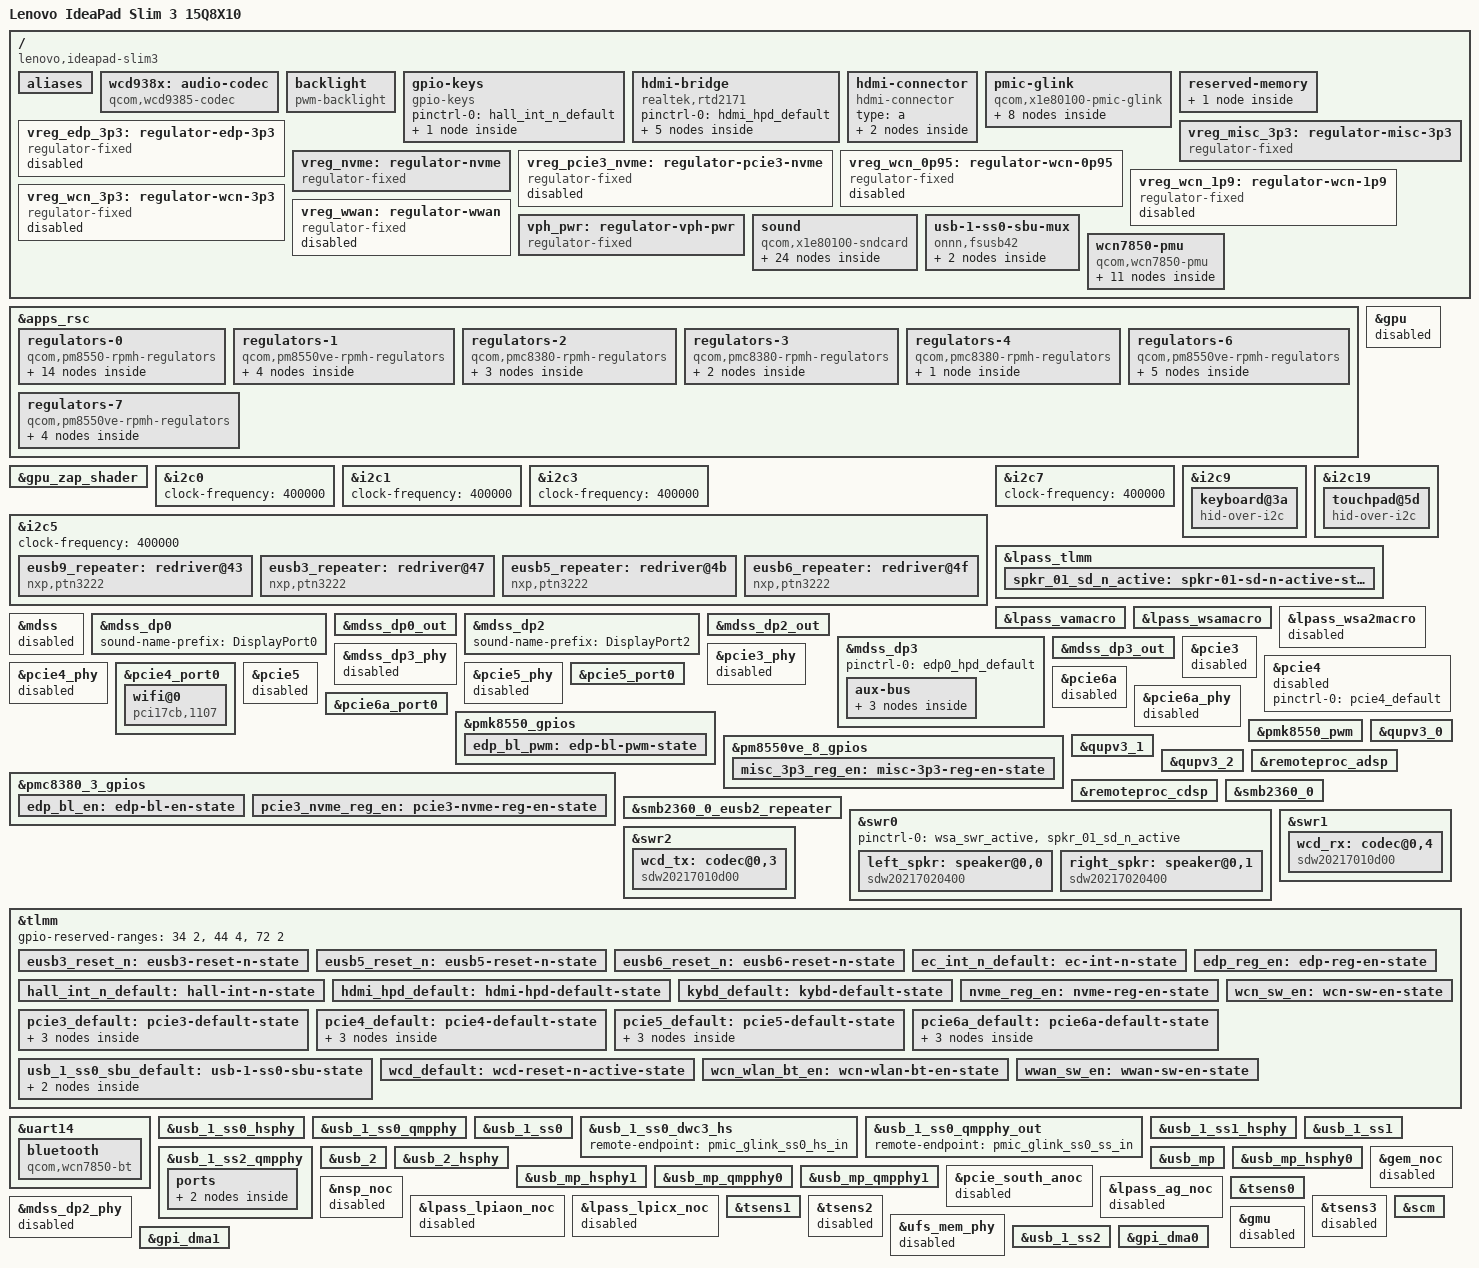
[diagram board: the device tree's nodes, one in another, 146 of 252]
// SPDX-License-Identifier: BSD-3-Clause
/*
 * Copyright (c) 2023 Qualcomm Innovation Center, Inc. All rights reserved.
 * Copyright (c) 2024, Linaro Limited
 * Copyright (c) 2025, Jens Glathe
 */

/dts-v1/;

#include <dt-bindings/gpio/gpio.h>
#include <dt-bindings/input/gpio-keys.h>
#include <dt-bindings/input/input.h>
#include <dt-bindings/pinctrl/qcom,pmic-gpio.h>
#include <dt-bindings/regulator/qcom,rpmh-regulator.h>

#include "purwa.dtsi"
#include "hamoa-pmics.dtsi"

/delete-node/ &pmc8380_6;
/delete-node/ &pmc8380_6_thermal;

/ {
	model = "Lenovo IdeaPad Slim 3 15Q8X10";
	compatible = "lenovo,ideapad-slim3", "lenovo,thinkpad-t14s", "qcom,x126100", "qcom,x1p42100";
	chassis-type = "laptop";

	aliases {
		serial0 = &uart21;
		serial1 = &uart14;
	};

	wcd938x: audio-codec {
		compatible = "qcom,wcd9385-codec";
		#sound-dai-cells = <1>;

		pinctrl-names = "default";
		pinctrl-0 = <&wcd_default>;

		qcom,micbias1-microvolt = <1800000>;
		qcom,micbias2-microvolt = <1800000>;
		qcom,micbias3-microvolt = <1800000>;
		qcom,micbias4-microvolt = <1800000>;
		qcom,mbhc-buttons-vthreshold-microvolt = <75000 150000 237000 500000 500000 500000 500000 500000>;
		qcom,mbhc-headset-vthreshold-microvolt = <1700000>;
		qcom,mbhc-headphone-vthreshold-microvolt = <50000>;
		qcom,rx-device = <&wcd_rx>;
		qcom,tx-device = <&wcd_tx>;

		reset-gpios = <&tlmm 191 GPIO_ACTIVE_LOW>;

		vdd-buck-supply = <&vreg_l15b_1p8>;
		vdd-rxtx-supply = <&vreg_l15b_1p8>;
		vdd-io-supply = <&vreg_l15b_1p8>;
		vdd-mic-bias-supply = <&vreg_bob1>;
	};

	backlight: backlight {
		compatible = "pwm-backlight";
		pwms = <&pmk8550_pwm 0 5000000>;
		pinctrl-0 = <&edp_bl_pwm>;
		pinctrl-names = "default";
	};

	gpio-keys {
		compatible = "gpio-keys";

		pinctrl-0 = <&hall_int_n_default>;
		pinctrl-names = "default";

		switch-lid {
			gpios = <&tlmm 92 GPIO_ACTIVE_LOW>;
			linux,input-type = <EV_SW>;
			linux,code = <SW_LID>;
			wakeup-source;
			wakeup-event-action = <EV_ACT_DEASSERTED>;
		};
	};

	hdmi-bridge {
		compatible = "realtek,rtd2171";

		pinctrl-0 = <&hdmi_hpd_default>;
		pinctrl-names = "default";

		ports {
			#address-cells = <1>;
			#size-cells = <0>;

			port@0 {
				reg = <0>;

				hdmi_bridge_dp_in: endpoint {
					remote-endpoint = <&usb_1_ss2_qmpphy_out_dp>;
				};
			};

			port@1 {
				reg = <1>;

				hdmi_bridge_tmds_out: endpoint {
					remote-endpoint = <&hdmi_con>;
				};
			};
		};
	};

	hdmi-connector {
		compatible = "hdmi-connector";
		type = "a";

		port {
			hdmi_con: endpoint {
				remote-endpoint = <&hdmi_bridge_tmds_out>;
			};
		};
	};

	pmic-glink {
		compatible = "qcom,x1e80100-pmic-glink",
				"qcom,pmic-glink";
		#address-cells = <1>;
		#size-cells = <0>;
		orientation-gpios = <&tlmm 121 GPIO_ACTIVE_HIGH>,
				<&tlmm 123 GPIO_ACTIVE_HIGH>,
				<&tlmm 125 GPIO_ACTIVE_HIGH>;

		connector@0 {
			compatible = "usb-c-connector";
			reg = <0>;
			power-role = "dual";
			data-role = "host";

			ports {
				#address-cells = <1>;
				#size-cells = <0>;

				port@0 {
					reg = <0>;

					pmic_glink_ss0_hs_in: endpoint {
						remote-endpoint = <&usb_1_ss0_dwc3_hs>;
					};
				};

				port@1 {
					reg = <1>;

					pmic_glink_ss0_ss_in: endpoint {
						remote-endpoint = <&usb_1_ss0_qmpphy_out>;
					};
				};

				port@2 {
					reg = <2>;

					pmic_glink_ss0_sbu: endpoint {
						remote-endpoint = <&usb_1_ss0_sbu_mux>;
					};
				};
			};
		};
	};

	reserved-memory {
		linux,cma {
			compatible = "shared-dma-pool";
			size = <0x0 0x8000000>;
			reusable;
			linux,cma-default;
		};
	};

	vreg_edp_3p3: regulator-edp-3p3 {
		compatible = "regulator-fixed";

		regulator-name = "VREG_EDP_3P3";
		regulator-min-microvolt = <3300000>;
		regulator-max-microvolt = <3300000>;

		gpio = <&tlmm 70 GPIO_ACTIVE_HIGH>;
		enable-active-high;

		pinctrl-0 = <&edp_reg_en>;
		pinctrl-names = "default";

		regulator-boot-on;
	};

	vreg_misc_3p3: regulator-misc-3p3 {
		compatible = "regulator-fixed";

		regulator-name = "VREG_MISC_3P3";
		regulator-min-microvolt = <3300000>;
		regulator-max-microvolt = <3300000>;

		gpio = <&pm8550ve_8_gpios 6 GPIO_ACTIVE_HIGH>;
		enable-active-high;

		pinctrl-names = "default";
		pinctrl-0 = <&misc_3p3_reg_en>;

		regulator-boot-on;
		regulator-always-on;
	};

	vreg_nvme: regulator-nvme {
		compatible = "regulator-fixed";

		regulator-name = "VREG_NVME_3P3";
		regulator-min-microvolt = <3300000>;
		regulator-max-microvolt = <3300000>;

		gpio = <&tlmm 18 GPIO_ACTIVE_HIGH>;
		enable-active-high;

		pinctrl-0 = <&nvme_reg_en>;
		pinctrl-names = "default";

		regulator-boot-on;
		regulator-always-on;
	};

	vreg_pcie3_nvme: regulator-pcie3-nvme {
		compatible = "regulator-fixed";

		regulator-name = "VREG_PCIE3_NVME_3P3";
		regulator-min-microvolt = <3300000>;
		regulator-max-microvolt = <3300000>;

		gpio = <&pmc8380_3_gpios 5 GPIO_ACTIVE_HIGH>;
		enable-active-high;

		pinctrl-0 = <&pcie3_nvme_reg_en>;
		pinctrl-names = "default";

		startup-delay-us = <2000000>;

		regulator-boot-on;
		regulator-always-on;
	};

	vreg_wcn_0p95: regulator-wcn-0p95 {
		compatible = "regulator-fixed";

		regulator-name = "VREG_WCN_0P95";
		regulator-min-microvolt = <950000>;
		regulator-max-microvolt = <950000>;

		vin-supply = <&vreg_wcn_3p3>;
	};

	vreg_wcn_1p9: regulator-wcn-1p9 {
		compatible = "regulator-fixed";

		regulator-name = "VREG_WCN_1P9";
		regulator-min-microvolt = <1900000>;
		regulator-max-microvolt = <1900000>;

		vin-supply = <&vreg_wcn_3p3>;
	};

	vreg_wcn_3p3: regulator-wcn-3p3 {
		compatible = "regulator-fixed";

		regulator-name = "VREG_WCN_3P3";
		regulator-min-microvolt = <3300000>;
		regulator-max-microvolt = <3300000>;

		gpio = <&tlmm 214 GPIO_ACTIVE_HIGH>;
		enable-active-high;

		pinctrl-0 = <&wcn_sw_en>;
		pinctrl-names = "default";

		regulator-boot-on;
	};

	vreg_wwan: regulator-wwan {
		compatible = "regulator-fixed";

		regulator-name = "VCC3B_WAN_RCM";
		regulator-min-microvolt = <3300000>;
		regulator-max-microvolt = <3300000>;

		gpio = <&tlmm 221 GPIO_ACTIVE_HIGH>;
		enable-active-high;

		pinctrl-0 = <&wwan_sw_en>;
		pinctrl-names = "default";

		regulator-boot-on;
	};

	vph_pwr: regulator-vph-pwr {
		compatible = "regulator-fixed";

		regulator-name = "vph_pwr";
		regulator-min-microvolt = <3700000>;
		regulator-max-microvolt = <3700000>;

		regulator-always-on;
		regulator-boot-on;
	};

	sound {
		compatible = "qcom,x1e80100-sndcard";
		model = "X1E80100-LENOVO-Ideapad-3";
		audio-routing = "SpkrLeft IN", "WSA WSA_SPK1 OUT",
				"SpkrRight IN", "WSA WSA_SPK2 OUT",
				"IN1_HPHL", "HPHL_OUT",
				"IN2_HPHR", "HPHR_OUT",
				"AMIC2", "MIC BIAS2",
				"VA DMIC0", "MIC BIAS3",
				"VA DMIC1", "MIC BIAS3",
				"VA DMIC0", "VA MIC BIAS1",
				"VA DMIC1", "VA MIC BIAS1",
				"TX SWR_INPUT1", "ADC2_OUTPUT";

		displayport-0-dai-link {
			link-name = "DisplayPort0 Playback";

			codec {
				sound-dai = <&mdss_dp0>;
			};

			cpu {
				sound-dai = <&q6apmbedai DISPLAY_PORT_RX_0>;
			};

			platform {
				sound-dai = <&q6apm>;
			};
		};

		displayport-2-dai-link {
			link-name = "DisplayPort2 Playback";

			codec {
				sound-dai = <&mdss_dp2>;
			};

			cpu {
				sound-dai = <&q6apmbedai DISPLAY_PORT_RX_2>;
			};

			platform {
				sound-dai = <&q6apm>;
			};
		};

		wcd-playback-dai-link {
			link-name = "WCD Playback";

			cpu {
				sound-dai = <&q6apmbedai RX_CODEC_DMA_RX_0>;
			};

			codec {
				sound-dai = <&wcd938x 0>, <&swr1 0>, <&lpass_rxmacro 0>;
			};

			platform {
				sound-dai = <&q6apm>;
			};
		};

		wcd-capture-dai-link {
			link-name = "WCD Capture";

			cpu {
				sound-dai = <&q6apmbedai TX_CODEC_DMA_TX_3>;
			};

			codec {
				sound-dai = <&wcd938x 1>, <&swr2 1>, <&lpass_txmacro 0>;
			};

			platform {
				sound-dai = <&q6apm>;
			};
		};

		wsa-dai-link {
			link-name = "WSA Playback";

			cpu {
				sound-dai = <&q6apmbedai WSA_CODEC_DMA_RX_0>;
			};

			codec {
				sound-dai = <&left_spkr>, <&right_spkr>, <&swr0 0>, <&lpass_wsamacro 0>;
			};

			platform {
				sound-dai = <&q6apm>;
			};
		};

		va-dai-link {
			link-name = "VA Capture";

			cpu {
				sound-dai = <&q6apmbedai VA_CODEC_DMA_TX_0>;
			};

			codec {
				sound-dai = <&lpass_vamacro 0>;
			};

			platform {
				sound-dai = <&q6apm>;
			};
		};
	};

	usb-1-ss0-sbu-mux {
		compatible = "onnn,fsusb42", "gpio-sbu-mux";

		enable-gpios = <&tlmm 168 GPIO_ACTIVE_LOW>;
		select-gpios = <&tlmm 167 GPIO_ACTIVE_HIGH>;

		pinctrl-0 = <&usb_1_ss0_sbu_default>;
		pinctrl-names = "default";

		mode-switch;
		orientation-switch;

		port {
			usb_1_ss0_sbu_mux: endpoint {
				remote-endpoint = <&pmic_glink_ss0_sbu>;
			};
		};
	};

	wcn7850-pmu {
		compatible = "qcom,wcn7850-pmu";

		vdd-supply = <&vreg_wcn_0p95>;
		vddio-supply = <&vreg_l15b_1p8>;
		vddaon-supply = <&vreg_wcn_0p95>;
		vdddig-supply = <&vreg_wcn_0p95>;
		vddrfa1p2-supply = <&vreg_wcn_1p9>;
		vddrfa1p8-supply = <&vreg_wcn_1p9>;

		wlan-enable-gpios = <&tlmm 117 GPIO_ACTIVE_HIGH>;
		bt-enable-gpios = <&tlmm 116 GPIO_ACTIVE_HIGH>;

		pinctrl-0 = <&wcn_wlan_bt_en>;
		pinctrl-names = "default";

		regulators {
			vreg_pmu_rfa_cmn: ldo0 {
				regulator-name = "vreg_pmu_rfa_cmn";
			};

			vreg_pmu_aon_0p59: ldo1 {
				regulator-name = "vreg_pmu_aon_0p59";
			};

			vreg_pmu_wlcx_0p8: ldo2 {
				regulator-name = "vreg_pmu_wlcx_0p8";
			};

			vreg_pmu_wlmx_0p85: ldo3 {
				regulator-name = "vreg_pmu_wlmx_0p85";
			};

			vreg_pmu_btcmx_0p85: ldo4 {
				regulator-name = "vreg_pmu_btcmx_0p85";
			};

			vreg_pmu_rfa_0p8: ldo5 {
				regulator-name = "vreg_pmu_rfa_0p8";
			};

			vreg_pmu_rfa_1p2: ldo6 {
				regulator-name = "vreg_pmu_rfa_1p2";
			};

			vreg_pmu_rfa_1p8: ldo7 {
				regulator-name = "vreg_pmu_rfa_1p8";
			};

			vreg_pmu_pcie_0p9: ldo8 {
				regulator-name = "vreg_pmu_pcie_0p9";
			};

			vreg_pmu_pcie_1p8: ldo9 {
				regulator-name = "vreg_pmu_pcie_1p8";
			};
		};
	};
};

&apps_rsc {
	regulators-0 {
		compatible = "qcom,pm8550-rpmh-regulators";
		qcom,pmic-id = "b";

		vdd-bob1-supply = <&vph_pwr>;
		vdd-bob2-supply = <&vph_pwr>;
		vdd-l1-l4-l10-supply = <&vreg_s4c_1p8>;
		vdd-l2-l13-l14-supply = <&vreg_bob1>;
		vdd-l5-l16-supply = <&vreg_bob1>;
		vdd-l6-l7-supply = <&vreg_bob2>;
		vdd-l8-l9-supply = <&vreg_bob1>;
		vdd-l12-supply = <&vreg_s5j_1p2>;
		vdd-l15-supply = <&vreg_s4c_1p8>;
		vdd-l17-supply = <&vreg_bob2>;

		vreg_bob1: bob1 {
			regulator-name = "vreg_bob1";
			regulator-min-microvolt = <3008000>;
			regulator-max-microvolt = <3960000>;
			regulator-initial-mode = <RPMH_REGULATOR_MODE_HPM>;
		};

		vreg_bob2: bob2 {
			regulator-name = "vreg_bob2";
			regulator-min-microvolt = <2504000>;
			regulator-max-microvolt = <3008000>;
			regulator-initial-mode = <RPMH_REGULATOR_MODE_HPM>;
		};

		vreg_l1b_1p8: ldo1 {
			regulator-name = "vreg_l1b_1p8";
			regulator-min-microvolt = <1800000>;
			regulator-max-microvolt = <1800000>;
			regulator-initial-mode = <RPMH_REGULATOR_MODE_HPM>;
		};

		vreg_l2b_3p0: ldo2 {
			regulator-name = "vreg_l2b_3p0";
			regulator-min-microvolt = <3072000>;
			regulator-max-microvolt = <3072000>;
			regulator-initial-mode = <RPMH_REGULATOR_MODE_HPM>;
		};

		vreg_l4b_1p8: ldo4 {
			regulator-name = "vreg_l4b_1p8";
			regulator-min-microvolt = <1800000>;
			regulator-max-microvolt = <1800000>;
			regulator-initial-mode = <RPMH_REGULATOR_MODE_HPM>;
		};

		vreg_l6b_1p8: ldo6 {
			regulator-name = "vreg_l6b_1p8";
			regulator-min-microvolt = <1800000>;
			regulator-max-microvolt = <2960000>;
			regulator-initial-mode = <RPMH_REGULATOR_MODE_HPM>;
		};

		vreg_l8b_3p0: ldo8 {
			regulator-name = "vreg_l8b_3p0";
			regulator-min-microvolt = <3072000>;
			regulator-max-microvolt = <3072000>;
			regulator-initial-mode = <RPMH_REGULATOR_MODE_HPM>;
		};

		vreg_l9b_2p9: ldo9 {
			regulator-name = "vreg_l9b_2p9";
			regulator-min-microvolt = <2960000>;
			regulator-max-microvolt = <2960000>;
			regulator-initial-mode = <RPMH_REGULATOR_MODE_HPM>;
		};

		vreg_l10b_1p8: ldo10 {
			regulator-name = "vreg_l10b_1p8";
			regulator-min-microvolt = <1800000>;
			regulator-max-microvolt = <1800000>;
			regulator-initial-mode = <RPMH_REGULATOR_MODE_HPM>;
		};

		vreg_l12b_1p2: ldo12 {
			regulator-name = "vreg_l12b_1p2";
			regulator-min-microvolt = <1150000>;
			regulator-max-microvolt = <1250000>;
			regulator-initial-mode = <RPMH_REGULATOR_MODE_HPM>;
			regulator-always-on;
		};

		vreg_l13b_3p0: ldo13 {
			regulator-name = "vreg_l13b_3p0";
			regulator-min-microvolt = <3072000>;
			regulator-max-microvolt = <3072000>;
			regulator-initial-mode = <RPMH_REGULATOR_MODE_HPM>;
		};

		vreg_l14b_3p0: ldo14 {
			regulator-name = "vreg_l14b_3p0";
			regulator-min-microvolt = <3072000>;
			regulator-max-microvolt = <3072000>;
			regulator-initial-mode = <RPMH_REGULATOR_MODE_HPM>;
		};

		vreg_l15b_1p8: ldo15 {
			regulator-name = "vreg_l15b_1p8";
			regulator-min-microvolt = <1800000>;
			regulator-max-microvolt = <1800000>;
			regulator-initial-mode = <RPMH_REGULATOR_MODE_HPM>;
			regulator-always-on;
		};

		vreg_l17b_2p5: ldo17 {
			regulator-name = "vreg_l17b_2p5";
			regulator-min-microvolt = <2504000>;
			regulator-max-microvolt = <2504000>;
			regulator-initial-mode = <RPMH_REGULATOR_MODE_HPM>;
		};
	};

	regulators-1 {
		compatible = "qcom,pm8550ve-rpmh-regulators";
		qcom,pmic-id = "c";

		vdd-l1-supply = <&vreg_s5j_1p2>;
		vdd-l2-supply = <&vreg_s1f_0p7>;
		vdd-l3-supply = <&vreg_s1f_0p7>;
		vdd-s4-supply = <&vph_pwr>;

		vreg_s4c_1p8: smps4 {
			regulator-name = "vreg_s4c_1p8";
			regulator-min-microvolt = <1856000>;
			regulator-max-microvolt = <2000000>;
			regulator-initial-mode = <RPMH_REGULATOR_MODE_HPM>;
		};

		vreg_l1c_1p2: ldo1 {
			regulator-name = "vreg_l1c_1p2";
			regulator-min-microvolt = <1200000>;
			regulator-max-microvolt = <1200000>;
			regulator-initial-mode = <RPMH_REGULATOR_MODE_HPM>;
		};

		vreg_l2c_0p8: ldo2 {
			regulator-name = "vreg_l2c_0p8";
			regulator-min-microvolt = <880000>;
			regulator-max-microvolt = <880000>;
			regulator-initial-mode = <RPMH_REGULATOR_MODE_HPM>;
		};

		vreg_l3c_0p8: ldo3 {
			regulator-name = "vreg_l3c_0p8";
			regulator-min-microvolt = <912000>;
			regulator-max-microvolt = <912000>;
			regulator-initial-mode = <RPMH_REGULATOR_MODE_HPM>;
		};
	};

	regulators-2 {
		compatible = "qcom,pmc8380-rpmh-regulators";
		qcom,pmic-id = "d";

		vdd-l1-supply = <&vreg_s1f_0p7>;
		vdd-l2-supply = <&vreg_s1f_0p7>;
		vdd-l3-supply = <&vreg_s4c_1p8>;
		vdd-s1-supply = <&vph_pwr>;

		vreg_l1d_0p8: ldo1 {
			regulator-name = "vreg_l1d_0p8";
			regulator-min-microvolt = <880000>;
			regulator-max-microvolt = <880000>;
			regulator-initial-mode = <RPMH_REGULATOR_MODE_HPM>;
		};

		vreg_l2d_0p9: ldo2 {
			regulator-name = "vreg_l2d_0p9";
			regulator-min-microvolt = <912000>;
			regulator-max-microvolt = <912000>;
			regulator-initial-mode = <RPMH_REGULATOR_MODE_HPM>;
		};

		vreg_l3d_1p8: ldo3 {
			regulator-name = "vreg_l3d_1p8";
			regulator-min-microvolt = <1800000>;
			regulator-max-microvolt = <1800000>;
			regulator-initial-mode = <RPMH_REGULATOR_MODE_HPM>;
		};
	};

	regulators-3 {
		compatible = "qcom,pmc8380-rpmh-regulators";
		qcom,pmic-id = "e";

		vdd-l2-supply = <&vreg_s1f_0p7>;
		vdd-l3-supply = <&vreg_s5j_1p2>;

		vreg_l2e_0p8: ldo2 {
			regulator-name = "vreg_l2e_0p8";
			regulator-min-microvolt = <880000>;
			regulator-max-microvolt = <880000>;
			regulator-initial-mode = <RPMH_REGULATOR_MODE_HPM>;
		};

		vreg_l3e_1p2: ldo3 {
			regulator-name = "vreg_l3e_1p2";
			regulator-min-microvolt = <1200000>;
			regulator-max-microvolt = <1200000>;
			regulator-initial-mode = <RPMH_REGULATOR_MODE_HPM>;
		};
	};

	regulators-4 {
		compatible = "qcom,pmc8380-rpmh-regulators";
		qcom,pmic-id = "f";

		vdd-l1-supply = <&vreg_s5j_1p2>;
		vdd-l2-supply = <&vreg_s5j_1p2>;
		vdd-l3-supply = <&vreg_s5j_1p2>;
		vdd-s1-supply = <&vph_pwr>;

		vreg_s1f_0p7: smps1 {
			regulator-name = "vreg_s1f_0p7";
			regulator-min-microvolt = <700000>;
			regulator-max-microvolt = <1100000>;
			regulator-initial-mode = <RPMH_REGULATOR_MODE_HPM>;
		};
	};

	regulators-6 {
		compatible = "qcom,pm8550ve-rpmh-regulators";
		qcom,pmic-id = "i";

		vdd-l1-supply = <&vreg_s4c_1p8>;
		vdd-l2-supply = <&vreg_s5j_1p2>;
		vdd-l3-supply = <&vreg_s1f_0p7>;
		vdd-s1-supply = <&vph_pwr>;
		vdd-s2-supply = <&vph_pwr>;

		vreg_l1i_1p8: ldo1 {
			regulator-name = "vreg_l1i_1p8";
			regulator-min-microvolt = <1750000>;
			regulator-max-microvolt = <1850000>;
			regulator-initial-mode = <RPMH_REGULATOR_MODE_HPM>;
			regulator-always-on;
		};

		vreg_l2i_1p2: ldo2 {
			regulator-name = "vreg_l2i_1p2";
			regulator-min-microvolt = <1200000>;
			regulator-max-microvolt = <1200000>;
			regulator-initial-mode = <RPMH_REGULATOR_MODE_HPM>;
		};

		vreg_l3i_0p8: ldo3 {
			regulator-name = "vreg_l3i_0p8";
			regulator-min-microvolt = <880000>;
			regulator-max-microvolt = <880000>;
			regulator-initial-mode = <RPMH_REGULATOR_MODE_HPM>;
		};

		vreg_s1i_0p9: smps1 {
			regulator-name = "vreg_s1i_0p9";
			regulator-min-microvolt = <900000>;
			regulator-max-microvolt = <920000>;
			regulator-initial-mode = <RPMH_REGULATOR_MODE_HPM>;
		};

		vreg_s2i_1p0: smps2 {
			regulator-name = "vreg_s2i_1p0";
			regulator-min-microvolt = <1000000>;
			regulator-max-microvolt = <1100000>;
			regulator-initial-mode = <RPMH_REGULATOR_MODE_HPM>;
		};
	};

	regulators-7 {
		compatible = "qcom,pm8550ve-rpmh-regulators";
		qcom,pmic-id = "j";

		vdd-l1-supply = <&vreg_s1f_0p7>;
		vdd-l2-supply = <&vreg_s5j_1p2>;
		vdd-l3-supply = <&vreg_s1f_0p7>;
		vdd-s5-supply = <&vph_pwr>;

		vreg_s5j_1p2: smps5 {
			regulator-name = "vreg_s5j_1p2";
			regulator-min-microvolt = <1256000>;
			regulator-max-microvolt = <1304000>;
			regulator-initial-mode = <RPMH_REGULATOR_MODE_HPM>;
		};

		vreg_l1j_0p8: ldo1 {
			regulator-name = "vreg_l1j_0p8";
			regulator-min-microvolt = <912000>;
			regulator-max-microvolt = <912000>;
			regulator-initial-mode = <RPMH_REGULATOR_MODE_HPM>;
		};

		vreg_l2j_1p2: ldo2 {
			regulator-name = "vreg_l2j_1p2";
			regulator-min-microvolt = <1256000>;
			regulator-max-microvolt = <1256000>;
			regulator-initial-mode = <RPMH_REGULATOR_MODE_HPM>;
		};

		vreg_l3j_0p8: ldo3 {
			regulator-name = "vreg_l3j_0p8";
			regulator-min-microvolt = <880000>;
			regulator-max-microvolt = <880000>;
			regulator-initial-mode = <RPMH_REGULATOR_MODE_HPM>;
		};
	};
};

&gpu {
	status = "okay";
};

&gpu_zap_shader {
	firmware-name = "qcom/x1p42100/LENOVO/83N3/qcdxkmsucpurwa.mbn";
};

&i2c0 {
/* unknown yet */
	clock-frequency = <400000>;

	status = "okay";
};

&i2c1 {
	clock-frequency = <400000>;

	status = "okay";

	/* 3d PS883x */
};

&i2c3 {
	clock-frequency = <400000>;

	status = "okay";

	/* 1st PS883x */
};

&i2c5 {
	clock-frequency = <400000>;

	status = "okay";

	eusb9_repeater: redriver@43 {
		compatible = "nxp,ptn3222";
		reg = <0x43>;
		#phy-cells = <0>;

		vdd3v3-supply = <&vreg_l13b_3p0>;
		vdd1v8-supply = <&vreg_l4b_1p8>;
	};

	eusb3_repeater: redriver@47 {
		compatible = "nxp,ptn3222";
		reg = <0x47>;
		#phy-cells = <0>;

		vdd3v3-supply = <&vreg_l13b_3p0>;
		vdd1v8-supply = <&vreg_l4b_1p8>;

		reset-gpios = <&tlmm 6 GPIO_ACTIVE_LOW>;

		pinctrl-0 = <&eusb3_reset_n>;
		pinctrl-names = "default";
	};

	eusb5_repeater: redriver@4b {
		compatible = "nxp,ptn3222";
		reg = <0x4b>;
		#phy-cells = <0>;

		vdd3v3-supply = <&vreg_l13b_3p0>;
		vdd1v8-supply = <&vreg_l4b_1p8>;

		reset-gpios = <&tlmm 7 GPIO_ACTIVE_LOW>;

		pinctrl-0 = <&eusb5_reset_n>;
		pinctrl-names = "default";
	};

	eusb6_repeater: redriver@4f {
		compatible = "nxp,ptn3222";
		reg = <0x4f>;
		#phy-cells = <0>;

		vdd3v3-supply = <&vreg_l13b_3p0>;
		vdd1v8-supply = <&vreg_l4b_1p8>;

		reset-gpios = <&tlmm 184 GPIO_ACTIVE_LOW>;

		pinctrl-0 = <&eusb6_reset_n>;
		pinctrl-names = "default";
	};

//	embedded-controller@76 {
//		compatible = "qcom,hamoa-crd-ec";
//		reg = <0x76>;
//
//		interrupts-extended = <&tlmm 66 IRQ_TYPE_EDGE_FALLING>;
//
//		pinctrl-0 = <&ec_int_n_default>;
//		pinctrl-names = "default";
//	};
};

&i2c7 {
	clock-frequency = <400000>;

	status = "okay";

	/* 2nd PS883x */
};

&i2c9 {
	clock-frequency = <400000>;

	pinctrl-0 = <&qup_i2c9_data_clk>;
	pinctrl-names = "default";
	status = "okay";

	keyboard@3a {
		compatible = "hid-over-i2c";
		reg = <0x3a>;

		hid-descr-addr = <0x1>;
		interrupts-extended = <&tlmm 67 IRQ_TYPE_LEVEL_LOW>;

		pinctrl-0 = <&kybd_default>;
		pinctrl-names = "default";

		vdd-supply = <&vreg_misc_3p3>;
		vddl-supply = <&vreg_l12b_1p2>;

		wakeup-source;
	};
};

&i2c19 {
	clock-frequency = <400000>;

	pinctrl-0 = <&qup_i2c19_data_clk>;
	pinctrl-names = "default";
	status = "okay";

//	/* ELAN06FA */
//	touchpad@15 {
//		compatible = "hid-over-i2c";
//		reg = <0x15>;
//
//		hid-descr-addr = <0x1>;
//		interrupts-extended = <&gpio67_irqmux 1>;
//
//		vdd-supply = <&vreg_misc_3p3>;
//		vddl-supply = <&vreg_l12b_1p2>;
//
//		wakeup-source;
//	};
//
//	/* CIRQ1080 or SYNA2BA6 */
//	touchpad@2c {
//		compatible = "hid-over-i2c";
//		reg = <0x2c>;
//
//		hid-descr-addr = <0x20>;
//		interrupts-extended = <&gpio67_irqmux 1>;
//
//		vdd-supply = <&vreg_misc_3p3>;
//		vddl-supply = <&vreg_l12b_1p2>;
//
//		wakeup-source;
//	};
//
//	/* FTCS0038 */
//	touchpad@38 {
//		compatible = "hid-over-i2c";
//		reg = <0x38>;
//
//		hid-descr-addr = <0x1>;
//		interrupts-extended = <&gpio67_irqmux 1>;
//
//		vdd-supply = <&vreg_misc_3p3>;
//		vddl-supply = <&vreg_l12b_1p2>;
//
//		wakeup-source;
//	};

	/* GXTP5100 */
	touchpad@5d {
		compatible = "hid-over-i2c";
		reg = <0x5d>;

		hid-descr-addr = <0x1>;

		vdd-supply = <&vreg_misc_3p3>;
		vddl-supply = <&vreg_l12b_1p2>;

	};
};

//&iris {
//	firmware-name = "qcom/x1p42100/LENOVO/83N3/qcvss8380.mbn";
//	status = "okay";
//};

&lpass_tlmm {
	spkr_01_sd_n_active: spkr-01-sd-n-active-state {
		pins = "gpio12";
		function = "gpio";
		drive-strength = <16>;
		bias-disable;
		output-low;
	};
};

&lpass_vamacro {
	pinctrl-0 = <&dmic01_default>;
	pinctrl-names = "default";

	vdd-micb-supply = <&vreg_l1b_1p8>;
	qcom,dmic-sample-rate = <4800000>;
};

&lpass_wsamacro {
	status = "okay";
	assigned-clocks = <&q6prmcc 0x42 0x01>;
	assigned-clock-rates = <19200000>;
	clock-output-names = "wsa-mclk";
	#clock-cells = <0>;
};

&lpass_wsa2macro {
	status = "disabled";
};

&mdss {
	status = "okay";
};

&mdss_dp0 {
	sound-name-prefix = "DisplayPort0";

	status = "okay";
};

&mdss_dp0_out {
	link-frequencies = /bits/ 64 <1620000000 2700000000 5400000000 8100000000>;
};

&mdss_dp2 {
	sound-name-prefix = "DisplayPort2";

	status = "okay";
};

&mdss_dp2_out {
	link-frequencies = /bits/ 64 <1620000000 2700000000 5400000000 8100000000>;
};

&mdss_dp3 {
	/delete-property/ #sound-dai-cells;

	pinctrl-0 = <&edp0_hpd_default>;
	pinctrl-names = "default";

	status = "okay";

	aux-bus {
		panel: panel {
			compatible = "edp-panel";
			backlight = <&backlight>;

			enable-gpios = <&pmc8380_3_gpios 4 GPIO_ACTIVE_HIGH>;
			pinctrl-0 = <&edp_bl_en>;
			pinctrl-names = "default";

			power-supply = <&vreg_edp_3p3>;

			port {
				edp_panel_in: endpoint {
					remote-endpoint = <&mdss_dp3_out>;
				};
			};
		};
	};
};

&mdss_dp3_out {
	data-lanes = <0 1 2 3>;
	link-frequencies = /bits/ 64 <1620000000 2700000000 5400000000 8100000000>;

	remote-endpoint = <&edp_panel_in>;
};

&mdss_dp3_phy {
	vdda-phy-supply = <&vreg_l3j_0p8>;
	vdda-pll-supply = <&vreg_l2j_1p2>;

	status = "okay";
};

&pcie3 {
	perst-gpios = <&tlmm 143 GPIO_ACTIVE_LOW>;
	wake-gpios = <&tlmm 145 GPIO_ACTIVE_LOW>;

	vddpe-3v3-supply = <&vreg_pcie3_nvme>;

	pinctrl-0 = <&pcie3_default>;
	pinctrl-names = "default";

	max-link-speed = <1>;
	status = "okay";
};

&pcie3_phy {
	vdda-phy-supply = <&vreg_l3c_0p8>;
	vdda-pll-supply = <&vreg_l3e_1p2>;
	vdda-qref-supply = <&vreg_l3j_0p8>;

	status = "okay";
};

&pcie4 {

	pinctrl-0 = <&pcie4_default>;
	pinctrl-names = "default";

	status = "okay";
};

&pcie4_phy {
	vdda-phy-supply = <&vreg_l3i_0p8>;
	vdda-pll-supply = <&vreg_l3e_1p2>;

	status = "okay";
};

&pcie4_port0 {
	reset-gpios = <&tlmm 146 GPIO_ACTIVE_LOW>;
	wake-gpios = <&tlmm 148 GPIO_ACTIVE_LOW>;

	wifi@0 {
		compatible = "pci17cb,1107";
		reg = <0x10000 0x0 0x0 0x0 0x0>;

		vddaon-supply = <&vreg_pmu_aon_0p59>;
		vddwlcx-supply = <&vreg_pmu_wlcx_0p8>;
		vddwlmx-supply = <&vreg_pmu_wlmx_0p85>;
		vddrfacmn-supply = <&vreg_pmu_rfa_cmn>;
		vddrfa0p8-supply = <&vreg_pmu_rfa_0p8>;
		vddrfa1p2-supply = <&vreg_pmu_rfa_1p2>;
		vddrfa1p8-supply = <&vreg_pmu_rfa_1p8>;
		vddpcie0p9-supply = <&vreg_pmu_pcie_0p9>;
		vddpcie1p8-supply = <&vreg_pmu_pcie_1p8>;
	};
};

&pcie5 {
	vddpe-3v3-supply = <&vreg_wwan>;

	pinctrl-0 = <&pcie5_default>;
	pinctrl-names = "default";

	status = "okay";
};

&pcie5_phy {
	vdda-phy-supply = <&vreg_l3i_0p8>;
	vdda-pll-supply = <&vreg_l3e_1p2>;

	status = "okay";
};

&pcie5_port0 {
	reset-gpios = <&tlmm 149 GPIO_ACTIVE_LOW>;
	wake-gpios = <&tlmm 151 GPIO_ACTIVE_LOW>;
};

&pcie6a {
	perst-gpios = <&tlmm 152 GPIO_ACTIVE_LOW>;
	wake-gpios = <&tlmm 154 GPIO_ACTIVE_LOW>;

	vddpe-3v3-supply = <&vreg_nvme>;

	pinctrl-0 = <&pcie6a_default>;
	pinctrl-names = "default";

	status = "okay";
};

&pcie6a_phy {
	vdda-phy-supply = <&vreg_l1d_0p8>;
	vdda-pll-supply = <&vreg_l2j_1p2>;

	status = "okay";
};

&pcie6a_port0 {
	reset-gpios = <&tlmm 152 GPIO_ACTIVE_LOW>;
	wake-gpios = <&tlmm 154 GPIO_ACTIVE_LOW>;
};

&pmk8550_gpios {
	edp_bl_pwm: edp-bl-pwm-state {
		pins = "gpio5";
		function = "func3";
	};
};

&pmk8550_pwm {
	status = "okay";
};


&pm8550ve_8_gpios {
	misc_3p3_reg_en: misc-3p3-reg-en-state {
		pins = "gpio6";
		function = "normal";
		bias-disable;
		drive-push-pull;
		input-disable;
		output-enable;
		power-source = <1>; /* 1.8 V */
		qcom,drive-strength = <PMIC_GPIO_STRENGTH_LOW>;
	};
};

&pmc8380_3_gpios {
	edp_bl_en: edp-bl-en-state {
		pins = "gpio4";
		function = "normal";
		power-source = <1>; /* 1.8V */
		input-disable;
		output-enable;
	};
	pcie3_nvme_reg_en: pcie3-nvme-reg-en-state {
		pins = "gpio5";
		function = "normal";
		power-source = <0>;
		input-disable;
		output-enable;
		drive-push-pull;
		bias-disable;
		qcom,drive-strength = <PMIC_GPIO_STRENGTH_LOW>;
	};
};

&qupv3_0 {
	status = "okay";
};

&qupv3_1 {
	status = "okay";
};

&qupv3_2 {
	status = "okay";
};

&remoteproc_adsp {
	firmware-name = "qcom/x1p42100/LENOVO/83N3/qcadsp8380.mbn",
			"qcom/x1p42100/LENOVO/83N3/adsp_dtbs.elf";

	status = "okay";
};

&remoteproc_cdsp {
	firmware-name = "qcom/x1p42100/LENOVO/83N3/qccdsp8380.mbn",
			"qcom/x1p42100/LENOVO/83N3/cdsp_dtbs.elf";

	status = "okay";
};

&smb2360_0 {
	status = "okay";
};

&smb2360_0_eusb2_repeater {
	vdd18-supply = <&vreg_l3d_1p8>;
	vdd3-supply = <&vreg_l2b_3p0>;
};

&swr0 {
	status = "okay";

	pinctrl-0 = <&wsa_swr_active>, <&spkr_01_sd_n_active>;
	pinctrl-names = "default";

	/* WSA8845, Left Speaker */
	left_spkr: speaker@0,0 {
		compatible = "sdw20217020400";
		reg = <0 0>;
		reset-gpios = <&lpass_tlmm 12 GPIO_ACTIVE_LOW>;
		#sound-dai-cells = <0>;
		sound-name-prefix = "SpkrLeft";
		vdd-1p8-supply = <&vreg_l15b_1p8>;
		vdd-io-supply = <&vreg_l12b_1p2>;
		qcom,port-mapping = <1 2 3 7 10 13>;
	};

	/* WSA8845, Right Speaker */
	right_spkr: speaker@0,1 {
		compatible = "sdw20217020400";
		reg = <0 1>;
		reset-gpios = <&lpass_tlmm 12 GPIO_ACTIVE_LOW>;
		#sound-dai-cells = <0>;
		sound-name-prefix = "SpkrRight";
		vdd-1p8-supply = <&vreg_l15b_1p8>;
		vdd-io-supply = <&vreg_l12b_1p2>;
		qcom,port-mapping = <4 5 6 7 11 13>;
	};
};

&swr1 {
	status = "okay";

	/* WCD9385 RX */
	wcd_rx: codec@0,4 {
		compatible = "sdw20217010d00";
		reg = <0 4>;
		qcom,rx-port-mapping = <1 2 3 4 5>;
	};
};

&swr2 {
	status = "okay";

	/* WCD9385 TX */
	wcd_tx: codec@0,3 {
		compatible = "sdw20217010d00";
		reg = <0 3>;
		qcom,tx-port-mapping = <2 2 3 4>;
	};
};

&tlmm {
	gpio-reserved-ranges = <34 2>, /* Unused */
		<44 4>, /* TPM SPI */
		<72 2>; /* Secure EC I2C connection (?) */

	eusb3_reset_n: eusb3-reset-n-state {
		pins = "gpio6";
		function = "gpio";
		drive-strength = <2>;
		bias-disable;
		output-low;
	};

	eusb5_reset_n: eusb5-reset-n-state {
		pins = "gpio7";
		function = "gpio";
		drive-strength = <2>;
		bias-disable;
		output-low;
	};

	eusb6_reset_n: eusb6-reset-n-state {
		pins = "gpio184";
		function = "gpio";
		drive-strength = <2>;
		bias-disable;
		output-low;
	};

	ec_int_n_default: ec-int-n-state {
		pins = "gpio66";
		function = "gpio";
		bias-disable;
	};

	edp_reg_en: edp-reg-en-state {
		pins = "gpio70";
		function = "gpio";
		drive-strength = <16>;
		bias-disable;
	};

	hall_int_n_default: hall-int-n-state {
		pins = "gpio92";
		function = "gpio";
		bias-disable;
	};

	hdmi_hpd_default: hdmi-hpd-default-state {
		pins = "gpio126";
		function = "usb2_dp";
		bias-disable;
	};

	kybd_default: kybd-default-state {
		pins = "gpio67";
		function = "gpio";
		bias-pull-up;
		drive-strength = <2>;
		input-enable;
	};

	nvme_reg_en: nvme-reg-en-state {
		pins = "gpio18";
		function = "gpio";
		drive-strength = <2>;
		bias-disable;
	};

	pcie3_default: pcie3-default-state {
		clkreq-n-pins {
			pins = "gpio144";
			function = "pcie3_clk";
			drive-strength = <2>;
			bias-pull-up;
		};

		perst-n-pins {
			pins = "gpio143";
			function = "gpio";
			drive-strength = <2>;
			bias-pull-down;
		};

		wake-n-pins {
			pins = "gpio145";
			function = "gpio";
			drive-strength = <2>;
			bias-pull-up;
		};
	};

	pcie4_default: pcie4-default-state {
		clkreq-n-pins {
			pins = "gpio147";
			function = "pcie4_clk";
			drive-strength = <2>;
			bias-pull-up;
		};

		perst-n-pins {
			pins = "gpio146";
			function = "gpio";
			drive-strength = <2>;
			bias-disable;
		};

		wake-n-pins {
			pins = "gpio148";
			function = "gpio";
			drive-strength = <2>;
			bias-pull-up;
		};
	};

	pcie5_default: pcie5-default-state {
		clkreq-n-pins {
			pins = "gpio150";
			function = "pcie5_clk";
			drive-strength = <2>;
			bias-pull-up;
		};

		perst-n-pins {
			pins = "gpio149";
			function = "gpio";
			drive-strength = <2>;
			bias-disable;
		};

		wake-n-pins {
			pins = "gpio151";
			function = "gpio";
			drive-strength = <2>;
			bias-pull-up;
		};
	};

	pcie6a_default: pcie6a-default-state {
		clkreq-n-pins {
			pins = "gpio153";
			function = "pcie6a_clk";
			drive-strength = <2>;
			bias-pull-up;
		};

		perst-n-pins {
			pins = "gpio152";
			function = "gpio";
			drive-strength = <2>;
			bias-disable;
		};

		wake-n-pins {
			pins = "gpio154";
			function = "gpio";
			drive-strength = <2>;
			bias-pull-up;
		};
	};

	usb_1_ss0_sbu_default: usb-1-ss0-sbu-state {
		oe-n-pins {
			pins = "gpio168";
			function = "gpio";
			bias-pull-up;
			drive-strength = <2>;
		};

		sel-pins {
			pins = "gpio167";
			function = "gpio";
			bias-pull-up;
			drive-strength = <2>;
		};

	};

	wcd_default: wcd-reset-n-active-state {
		pins = "gpio191";
		function = "gpio";
		drive-strength = <16>;
		bias-disable;
		output-low;
	};

	wcn_sw_en: wcn-sw-en-state {
		pins = "gpio214";
		function = "gpio";
		drive-strength = <2>;
		bias-disable;
	};

	wcn_wlan_bt_en: wcn-wlan-bt-en-state {
		pins = "gpio116", "gpio117";
		function = "gpio";
		drive-strength = <2>;
		bias-disable;
	};

	wwan_sw_en: wwan-sw-en-state {
		pins = "gpio221";
		function = "gpio";
		drive-strength = <4>;
		bias-disable;
	};
};

&uart14 {
	status = "okay";

	bluetooth {
		compatible = "qcom,wcn7850-bt";
		max-speed = <3200000>;

		vddaon-supply = <&vreg_pmu_aon_0p59>;
		vddwlcx-supply = <&vreg_pmu_wlcx_0p8>;
		vddwlmx-supply = <&vreg_pmu_wlmx_0p85>;
		vddrfacmn-supply = <&vreg_pmu_rfa_cmn>;
		vddrfa0p8-supply = <&vreg_pmu_rfa_0p8>;
		vddrfa1p2-supply = <&vreg_pmu_rfa_1p2>;
		vddrfa1p8-supply = <&vreg_pmu_rfa_1p8>;
	};
};

&usb_1_ss0_hsphy {
	vdd-supply = <&vreg_l3j_0p8>;
	vdda12-supply = <&vreg_l2j_1p2>;

	phys = <&smb2360_0_eusb2_repeater>;

	status = "okay";
};

&usb_1_ss0_qmpphy {
	vdda-phy-supply = <&vreg_l2j_1p2>;
	vdda-pll-supply = <&vreg_l1j_0p8>;

	status = "okay";
};

&usb_1_ss0 {
	status = "okay";

	dr_mode = "host";
};

&usb_1_ss0_dwc3_hs {
	remote-endpoint = <&pmic_glink_ss0_hs_in>;
};

&usb_1_ss0_qmpphy_out {
	remote-endpoint = <&pmic_glink_ss0_ss_in>;
};

&usb_1_ss1_hsphy {
	vdd-supply = <&vreg_l3j_0p8>;
	vdda12-supply = <&vreg_l2j_1p2>;

	phys = <&eusb9_repeater>;

	status = "okay";
};

&usb_1_ss1 {
	status = "okay";

	dr_mode = "host";
};

&usb_1_ss2_qmpphy {
	vdda-phy-supply = <&vreg_l2j_1p2>;
	vdda-pll-supply = <&vreg_l2d_0p9>;

	/delete-property/ mode-switch;
	/delete-property/ orientation-switch;

	status = "okay";

	ports {
		port@0 {
			#address-cells = <1>;
			#size-cells = <0>;

			/delete-node/ endpoint;

			usb_1_ss2_qmpphy_out_dp: endpoint@0 {
				reg = <0>;

//				data-lanes = <3 2 1 0>;
				remote-endpoint = <&hdmi_bridge_dp_in>;
			};

			/* No USB3 lanes connected */
		};
	};
};

&usb_2 {
	status = "okay";

	dr_mode = "host";
};

&usb_2_hsphy {
	vdd-supply = <&vreg_l2e_0p8>;
	vdda12-supply = <&vreg_l3e_1p2>;

	phys = <&eusb5_repeater>;

	status = "okay";
};

&usb_mp {
	status = "okay";
};

&usb_mp_hsphy0 {
	vdd-supply = <&vreg_l2e_0p8>;
	vdda12-supply = <&vreg_l3e_1p2>;

	phys = <&eusb3_repeater>;

	status = "okay";
};

&usb_mp_hsphy1 {
	vdd-supply = <&vreg_l2e_0p8>;
	vdda12-supply = <&vreg_l3e_1p2>;

	phys = <&eusb6_repeater>;

	status = "okay";
};

&usb_mp_qmpphy0 {
	vdda-phy-supply = <&vreg_l3e_1p2>;
	vdda-pll-supply = <&vreg_l3c_0p8>;

	status = "okay";
};

&usb_mp_qmpphy1 {
	vdda-phy-supply = <&vreg_l3e_1p2>;
	vdda-pll-supply = <&vreg_l3c_0p8>;

	status = "okay";
};

/* DIAGNOSTIC 2026-10-11: disable pcie_south_anoc to test whether its qnoc
 * probe is the silent-reset site observed right after the 1680000 probe.
 * Local-only experiment, not for publication. */
&pcie_south_anoc {
	status = "disabled";
};

/* DIAGNOSTIC 2026-10-11 (0007): disable the five tail NoCs (gem, nsp,
 * lpass ag/lpiaon/lpicx) to test whether a late qnoc probe is the
 * silent-reset site observed after the 1770000/1780000 probes.
 * Local-only experiment, not for publication. */
&gem_noc { status = "disabled"; };
&nsp_noc { status = "disabled"; };
&lpass_ag_noc { status = "disabled"; };
&lpass_lpiaon_noc { status = "disabled"; };
&lpass_lpicx_noc { status = "disabled"; };

/* DIAGNOSTIC 2026-10-15 (0008): minimal-boot round. Disable PCIe,
 * WLAN/WWAN/display/NVMe rails, thermal sensors, display and UFS
 * PHYs. Boot hung-on-reset right after the 9.45s regulator retry
 * burst; cut every non-essential pending family at once. USB and
 * core (clocks/pinctrl/SCM/PMIC) stay enabled. Local-only, not for
 * publication. */
&pcie3 { status = "disabled"; };
&pcie6a { status = "disabled"; };
&pcie5 { status = "disabled"; };
&pcie4 { status = "disabled"; };
&pcie3_phy { status = "disabled"; };
&pcie6a_phy { status = "disabled"; };
&pcie5_phy { status = "disabled"; };
&pcie4_phy { status = "disabled"; };
&vreg_edp_3p3 { status = "disabled"; };
&vreg_misc_3p3 { status = "disabled"; };
&vreg_pcie3_nvme { status = "disabled"; };
&vreg_wcn_0p95 { status = "disabled"; };
&vreg_wcn_1p9 { status = "disabled"; };
&vreg_wcn_3p3 { status = "disabled"; };
&vreg_wwan { status = "disabled"; };
&tsens0 { status = "disabled"; };
&tsens1 { status = "disabled"; };
&tsens2 { status = "disabled"; };
&tsens3 { status = "disabled"; };
&mdss_dp2_phy { status = "disabled"; };
&mdss_dp3_phy { status = "disabled"; };
&ufs_mem_phy { status = "disabled"; };

/* DIAGNOSTIC 2026-10-15 (0009): delete firmware:scm interconnects.
 * SCM's icc path (aggre2 + mc_virt) never resolves on this machine,
 * so SCM defers forever; the X1E PDC quirk hard-requires SCM, and
 * TLMM (wakeup-parent PDC), GPIO, USB PHYs and USB storage hang
 * behind it. devm_of_icc_get treats a missing property as no-vote
 * (NULL path), so SCM probes without bus voting. Local-only, not
 * for publication. */
&scm {
	/delete-property/ interconnects;
};

/* DIAGNOSTIC 2026-10-16 (0010): re-enable gem_noc. dwc3's apps-usb
 * icc path runs gem->config_noc, so the 0007 disable stalls USB
 * forever (no rootfs). If the 0.51s reset returns, gem was the
 * crasher and USB needs another route. Local-only, not for
 * publication. */
&gem_noc { status = "okay"; };

/* DIAGNOSTIC 2026-10-16 (0011): gem back off (its probe resets the
 * machine in 4s wall); reroute each dwc3 apps-usb path onto the
 * port's own usb-ddr pair so USB can bind without gem. Votes land
 * on the same working path twice (harmless for live boot).
 * Local-only, not for publication. */
&gem_noc { status = "disabled"; };
&usb_2 { interconnects = <0xe8 0x00 0x07 0x18 0x01 0x07 0xe8 0x00 0x07 0x18 0x01 0x07>; };
&usb_mp { interconnects = <0xe8 0x01 0x07 0x18 0x01 0x07 0xe8 0x01 0x07 0x18 0x01 0x07>; };
&usb_1_ss0 { interconnects = <0xe5 0x00 0x07 0x18 0x01 0x07 0xe5 0x00 0x07 0x18 0x01 0x07>; };
&usb_1_ss1 { interconnects = <0xe5 0x01 0x07 0x18 0x01 0x07 0xe5 0x01 0x07 0x18 0x01 0x07>; };

/* DIAGNOSTIC 2026-10-16 (0012): disable gpu + gmu. GPU binding to
 * its IOMMU group at ~9.26s is immediately followed by display
 * death (without SMMU the same boot lived to 19.4s+). Keep the
 * console on the firmware framebuffer until GPU/SMMU is properly
 * brought up. Local-only, not for publication. */
&gpu { status = "disabled"; };
&gmu { status = "disabled"; };

/* DIAGNOSTIC 2026-10-16 (0013): disable the display subsystem. The
 * mdss driver (from initramfs modules) binds the subsystem and takes
 * over the firmware framebuffer, but the panel never lights, so the
 * screen goes black-with-backlight and all later text is invisible.
 * Keep the console on simplefb until panel bring-up is solved.
 * Local-only, not for publication. */
&mdss { status = "disabled"; };

/* DIAGNOSTIC 2026-10-16 (0014): label-based USB reroute. Replaces
 * 0011, which used stale raw phandle numbers (one now resolves to
 * the cpucp mailbox, breaking path parsing). Each dwc3 apps-usb
 * path rerouted onto its own usb-ddr pair via &labels, which dtc
 * resolves at compile time. gem stays off. Local-only, not for
 * publication. */
&usb_1_ss2 { interconnects = <&usb_south_anoc MASTER_USB3_2 QCOM_ICC_TAG_ALWAYS &mc_virt SLAVE_EBI1 QCOM_ICC_TAG_ALWAYS>, <&usb_south_anoc MASTER_USB3_2 QCOM_ICC_TAG_ALWAYS &mc_virt SLAVE_EBI1 QCOM_ICC_TAG_ALWAYS>; };
&usb_2 { interconnects = <&usb_north_anoc MASTER_USB2 QCOM_ICC_TAG_ALWAYS &mc_virt SLAVE_EBI1 QCOM_ICC_TAG_ALWAYS>, <&usb_north_anoc MASTER_USB2 QCOM_ICC_TAG_ALWAYS &mc_virt SLAVE_EBI1 QCOM_ICC_TAG_ALWAYS>; };
&usb_mp { interconnects = <&usb_north_anoc MASTER_USB3_MP QCOM_ICC_TAG_ALWAYS &mc_virt SLAVE_EBI1 QCOM_ICC_TAG_ALWAYS>, <&usb_north_anoc MASTER_USB3_MP QCOM_ICC_TAG_ALWAYS &mc_virt SLAVE_EBI1 QCOM_ICC_TAG_ALWAYS>; };
&usb_1_ss0 { interconnects = <&usb_south_anoc MASTER_USB3_0 QCOM_ICC_TAG_ALWAYS &mc_virt SLAVE_EBI1 QCOM_ICC_TAG_ALWAYS>, <&usb_south_anoc MASTER_USB3_0 QCOM_ICC_TAG_ALWAYS &mc_virt SLAVE_EBI1 QCOM_ICC_TAG_ALWAYS>; };
&usb_1_ss1 { interconnects = <&usb_south_anoc MASTER_USB3_1 QCOM_ICC_TAG_ALWAYS &mc_virt SLAVE_EBI1 QCOM_ICC_TAG_ALWAYS>, <&usb_south_anoc MASTER_USB3_1 QCOM_ICC_TAG_ALWAYS &mc_virt SLAVE_EBI1 QCOM_ICC_TAG_ALWAYS>; };

/* DIAGNOSTIC 2026-10-16 (0015): apps-usb via config_noc. The 0014
 * duplicate-pair is rejected by the icc core (same route twice).
 * Point apps-usb at config_noc instead (stock shape, gem
 * replaced). If the graph lacks that link it still defers, and
 * the fallback is making apps-usb optional in dwc3-qcom.
 * Local-only, not for publication. */
&usb_1_ss2 { interconnects = <&usb_south_anoc MASTER_USB3_2 QCOM_ICC_TAG_ALWAYS &mc_virt SLAVE_EBI1 QCOM_ICC_TAG_ALWAYS>, <&usb_south_anoc MASTER_USB3_2 QCOM_ICC_TAG_ALWAYS &config_noc SLAVE_USB3_2 QCOM_ICC_TAG_ALWAYS>; };
&usb_2 { interconnects = <&usb_north_anoc MASTER_USB2 QCOM_ICC_TAG_ALWAYS &mc_virt SLAVE_EBI1 QCOM_ICC_TAG_ALWAYS>, <&usb_north_anoc MASTER_USB2 QCOM_ICC_TAG_ALWAYS &config_noc SLAVE_USB2 QCOM_ICC_TAG_ALWAYS>; };
&usb_mp { interconnects = <&usb_north_anoc MASTER_USB3_MP QCOM_ICC_TAG_ALWAYS &mc_virt SLAVE_EBI1 QCOM_ICC_TAG_ALWAYS>, <&usb_north_anoc MASTER_USB3_MP QCOM_ICC_TAG_ALWAYS &config_noc SLAVE_USB3_MP QCOM_ICC_TAG_ALWAYS>; };
&usb_1_ss0 { interconnects = <&usb_south_anoc MASTER_USB3_0 QCOM_ICC_TAG_ALWAYS &mc_virt SLAVE_EBI1 QCOM_ICC_TAG_ALWAYS>, <&usb_south_anoc MASTER_USB3_0 QCOM_ICC_TAG_ALWAYS &config_noc SLAVE_USB3_0 QCOM_ICC_TAG_ALWAYS>; };
&usb_1_ss1 { interconnects = <&usb_south_anoc MASTER_USB3_1 QCOM_ICC_TAG_ALWAYS &mc_virt SLAVE_EBI1 QCOM_ICC_TAG_ALWAYS>, <&usb_south_anoc MASTER_USB3_1 QCOM_ICC_TAG_ALWAYS &config_noc SLAVE_USB3_1 QCOM_ICC_TAG_ALWAYS>; };

/* DIAGNOSTIC (0018): bring up the USB repeater's GENI I2C5 dependency
 * closure without re-enabling the reset-associated GEM NoC. qup-config
 * directly references disabled gem_noc; qup-memory also crosses it.
 * Missing ICC properties produce NULL no-vote paths, handled by the GENI
 * and ICC APIs. Enable only the existing GPI0 provider used by channel 5;
 * retain its existing IOMMU mapping and channel mask. No PHY voltage,
 * connector wiring, or unrelated I2C/controller changes. Local-only.
 */
&i2c5 {
	/delete-property/ interconnects;
	/delete-property/ interconnect-names;
};

&gpi_dma0 {
	status = "okay";
};

/* DIAGNOSTIC (0019): restore only the configured I2C9 keyboard supply
 * and its existing GPI1 DMA provider. GEM remains disabled after native
 * resets; use the same narrowly scoped NULL/no-vote ICC path as I2C5.
 * Keep voltage, GPIO, IRQ, DMA channel/mask and IOMMU definitions intact.
 * No display, PCIe, NVMe or other controller enablement. Local-only.
 */
&vreg_misc_3p3 {
	status = "okay";
};

&i2c9 {
	/delete-property/ interconnects;
	/delete-property/ interconnect-names;
};

&gpi_dma1 {
	status = "okay";
};

/* DIAGNOSTIC (0020): restore only CPU thermal sensors TSENS0/1.
 * TSENS0/1 carry the configured CPU0/CPU1 core top/btm and
 * cpuss0/cpuss1 top/btm zones (20 types). TSENS2 (GPU/camera,
 * cooling-maps reference disabled GPU) and TSENS3 (physically
 * present/unconfigured per purwa.dtsi) stay disabled. No ICC,
 * clock, regulator, trip or cooling-map changes. Local-only.
 */
&tsens0 {
	status = "okay";
};

&tsens1 {
	status = "okay";
};
